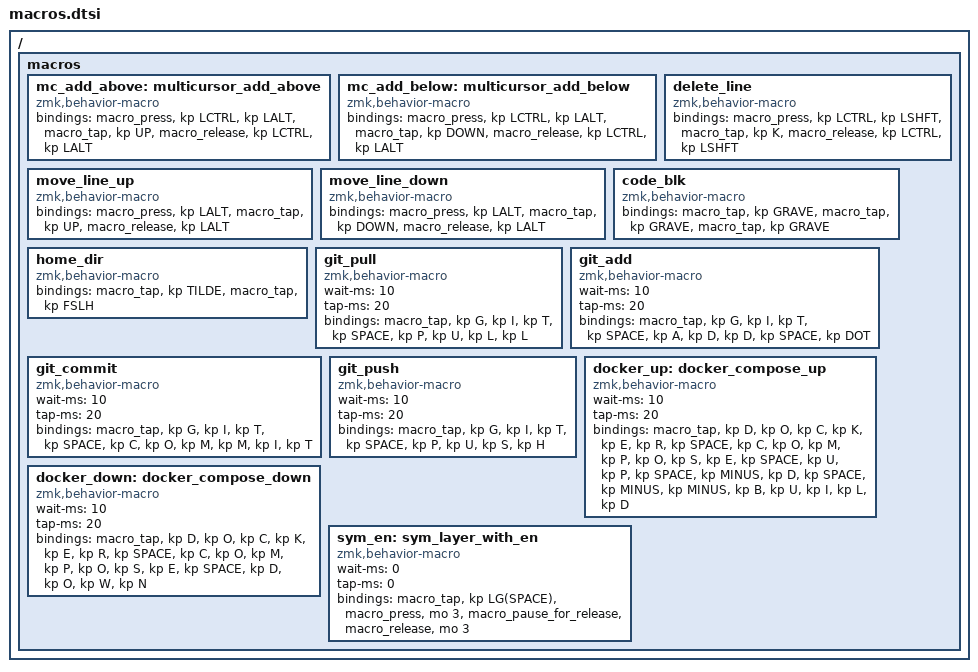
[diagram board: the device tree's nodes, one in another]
/ {
    macros {
        mc_add_above: multicursor_add_above {
            compatible = "zmk,behavior-macro";
            #binding-cells = <0>;
            bindings
                = <&macro_press &kp LCTRL &kp LALT>
                , <&macro_tap &kp UP>
                , <&macro_release &kp LCTRL &kp LALT>
                ;
        };

        mc_add_below: multicursor_add_below {
            compatible = "zmk,behavior-macro";
            #binding-cells = <0>;
            bindings
                = <&macro_press &kp LCTRL &kp LALT>
                , <&macro_tap &kp DOWN>
                , <&macro_release &kp LCTRL &kp LALT>
                ;
        };

        delete_line: delete_line {
            compatible = "zmk,behavior-macro";
            #binding-cells = <0>;
            bindings
                = <&macro_press &kp LCTRL &kp LSHFT>
                , <&macro_tap &kp K>
                , <&macro_release &kp LCTRL &kp LSHFT>
                ;
        };

        move_line_up: move_line_up {
            compatible = "zmk,behavior-macro";
            #binding-cells = <0>;
            bindings
                = <&macro_press &kp LALT>
                , <&macro_tap &kp UP>
                , <&macro_release &kp LALT>
                ;
        };

        move_line_down: move_line_down {
            compatible = "zmk,behavior-macro";
            #binding-cells = <0>;
            bindings
                = <&macro_press &kp LALT>
                , <&macro_tap &kp DOWN>
                , <&macro_release &kp LALT>
                ;
        };

        code_blk: code_blk {
            compatible = "zmk,behavior-macro";
            #binding-cells = <0>;
            bindings
                = <&macro_tap &kp GRAVE>
                , <&macro_tap &kp GRAVE>
                , <&macro_tap &kp GRAVE>
                ;
        };

        home_dir: home_dir {
            compatible = "zmk,behavior-macro";
            #binding-cells = <0>;
            bindings
                = <&macro_tap &kp TILDE>
                , <&macro_tap &kp FSLH>
                ;
        };

        git_pull: git_pull {
            compatible = "zmk,behavior-macro";
            #binding-cells = <0>;
            wait-ms = <10>;
            tap-ms = <20>;
            bindings = <
                &macro_tap &kp G &kp I &kp T &kp SPACE
                &kp P &kp U &kp L &kp L
            >;
        };

        git_add: git_add {
            compatible = "zmk,behavior-macro";
            #binding-cells = <0>;
            wait-ms = <10>;
            tap-ms = <20>;
            bindings = <
                &macro_tap &kp G &kp I &kp T &kp SPACE
                &kp A &kp D &kp D &kp SPACE &kp DOT
            >;
        };

        git_commit: git_commit {
            compatible = "zmk,behavior-macro";
            #binding-cells = <0>;
            wait-ms = <10>;
            tap-ms = <20>;
            bindings = <
                &macro_tap &kp G &kp I &kp T &kp SPACE
                &kp C &kp O &kp M &kp M &kp I &kp T
            >;
        };

        git_push: git_push {
            compatible = "zmk,behavior-macro";
            #binding-cells = <0>;
            wait-ms = <10>;
            tap-ms = <20>;
            bindings = <
                &macro_tap &kp G &kp I &kp T &kp SPACE
                &kp P &kp U &kp S &kp H
            >;
        };

        docker_up: docker_compose_up {
            compatible = "zmk,behavior-macro";
            #binding-cells = <0>;
            wait-ms = <10>;
            tap-ms = <20>;
            bindings = <
                &macro_tap &kp D &kp O &kp C &kp K &kp E &kp R &kp SPACE
                &kp C &kp O &kp M &kp P &kp O &kp S &kp E &kp SPACE
                &kp U &kp P &kp SPACE
                &kp MINUS &kp D &kp SPACE
                &kp MINUS &kp MINUS &kp B &kp U &kp I &kp L &kp D
            >;
        };

        docker_down: docker_compose_down {
            compatible = "zmk,behavior-macro";
            #binding-cells = <0>;
            wait-ms = <10>;
            tap-ms = <20>;
            bindings = <
                &macro_tap &kp D &kp O &kp C &kp K &kp E &kp R &kp SPACE
                &kp C &kp O &kp M &kp P &kp O &kp S &kp E &kp SPACE
                &kp D &kp O &kp W &kp N
            >;
        };

        sym_en: sym_layer_with_en {
            compatible = "zmk,behavior-macro";
            #binding-cells = <0>;
            wait-ms = <0>;
            tap-ms = <0>;
            bindings
                = <&macro_tap &kp LG(SPACE)>
                , <&macro_press &mo 3>
                , <&macro_pause_for_release>
                , <&macro_release &mo 3>
                ;
        };
    };
};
